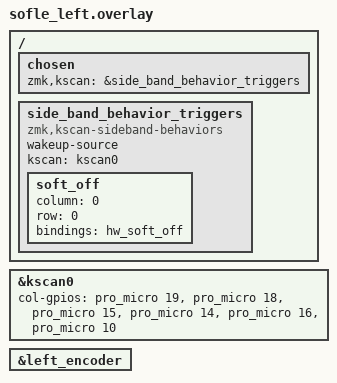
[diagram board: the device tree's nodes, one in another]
/*
 * Copyright (c) 2020 Ryan Cross
 *
 * SPDX-License-Identifier: MIT
 */

#include "sofle.dtsi"
/{
chosen {
        zmk,kscan = &side_band_behavior_triggers;
	};
};
&kscan0 {
    col-gpios
        = <&pro_micro 19 GPIO_ACTIVE_HIGH>
        , <&pro_micro 18 GPIO_ACTIVE_HIGH>
        , <&pro_micro 15 GPIO_ACTIVE_HIGH>
        , <&pro_micro 14 GPIO_ACTIVE_HIGH>
        , <&pro_micro 16 GPIO_ACTIVE_HIGH>
        , <&pro_micro 10 GPIO_ACTIVE_HIGH>
        ;
};

/{
	side_band_behavior_triggers: side_band_behavior_triggers {
		compatible = "zmk,kscan-sideband-behaviors";
		wakeup-source;
		kscan = <&kscan0>;
		soft_off {
			column = <0>;
			row = <0>;
			bindings = <&hw_soft_off>;
		};
	};

};

&left_encoder {
    status = "okay";
};
